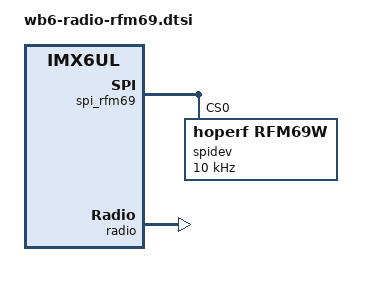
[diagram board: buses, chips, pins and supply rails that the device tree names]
/ {
    compatible = "contactless,imx6ul-wirenboard61", "contactless,imx6ul-wirenboard60", "contactless,imx6ul-wirenboard-evk", "fsl,imx6ul-14x14-evk", "fsl,imx6ul";

    /* Enable SPI for RFM module and add spidev node */
    fragment-wb6-rfm96h-spi {
        target = <&spi_rfm69>;

        __overlay__ {
            status = "okay";
            #address-cells = <1>;
            #size-cells = <0>;

            spidev@0 {
			    compatible = "hoperf,rfm69w";
			    spi-max-frequency = <10000>;
			    reg = <0>;
		    };
        };
    };

    fragment-wb6-rfm69h-status {
        target-path = "/wirenboard";

        __overlay__ {
            radio {
                status = "okay";
            };
        };
    };
};
